# BlockB: IP-XACT component
VLNV example.vendor:example_lib:BlockB:1.0

## Bus interfaces (logical=physical port)
register_if: slave example.vendor:example_lib:register_bus:1.0, memory map BlockB_map

## Address spaces and blocks
BlockB_map.BlockB_regs: base 0x0, range 0x100, width 32, register

## Registers
Registers are 32-bit, access per field, no defined reset value unless marked. A register's access mark holds for its fields unless they carry their own. Offsets are from the block's base; lines under a group give offsets from that group; [hi:lo] are bit positions; {n}, {i} and the like mark numbered series; 'fields as' and 'values as' point back to an identical list; <NAME> marks a mode.

## BlockB_map.BlockB_regs
Base 0x00000000
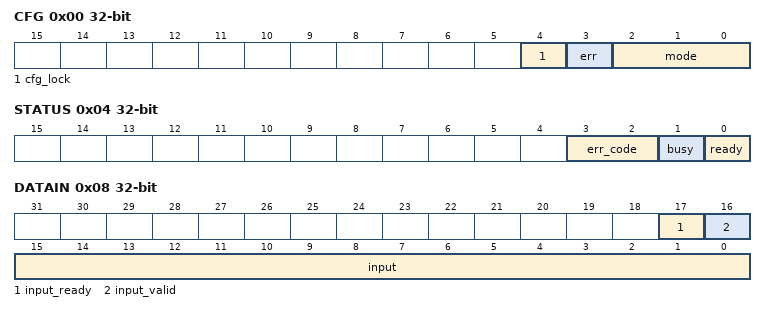
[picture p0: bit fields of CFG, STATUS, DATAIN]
0x00 CFG
  [4] cfg_lock wo, [3] err ro, [2:0] mode rw
0x04 STATUS
  [3:2] err_code wo, [1] busy rw, [0] ready ro
0x08 DATAIN
  [17] input_ready rw, [16] input_valid ro, [15:0] input wo
